# STM32U585 register map
File version: 1.4
CPU: CM33 r0p1, little endian, MPU, FPU, 4 interrupt priority bits
Registers are 32-bit, read-write, reset 0x0 unless marked. A register's access mark holds for its fields unless they carry their own. Offsets are from the block's base; [hi:lo] are bit positions; {n}, {i} and the like mark numbered series.

## ICACHE
Base 0x40030400
Same registers: SEC_ICache 0x50030400
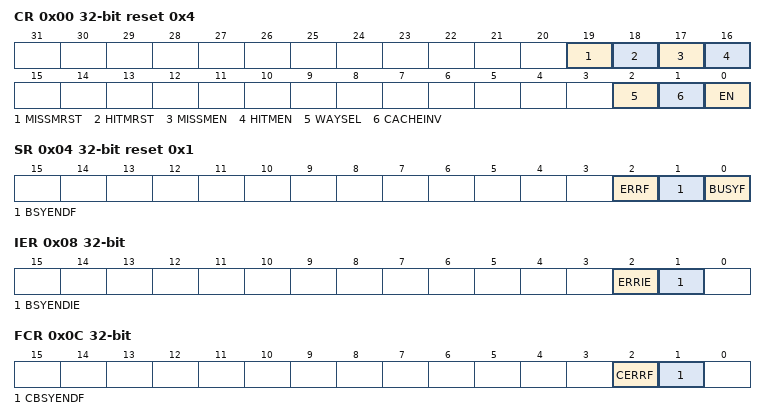
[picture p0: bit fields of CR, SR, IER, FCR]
0x00 CR access per field reset 0x4 — ICACHE control register
  [19] MISSMRST rw, [18] HITMRST rw, [17] MISSMEN rw, [16] HITMEN rw, [2] WAYSEL rw, [1] CACHEINV wo, [0] EN rw
0x04 SR ro reset 0x1 — ICACHE status register
  [2] ERRF, [1] BSYENDF, [0] BUSYF
0x08 IER — ICACHE interrupt enable register
  [2] ERRIE, [1] BSYENDIE
0x0C FCR wo — ICACHE flag clear register
  [2] CERRF, [1] CBSYENDF
0x10 HMONR ro — ICACHE hit monitor register
  [31:0] HITMON
0x14 MMONR ro — ICACHE miss monitor register
  [15:0] MISSMON
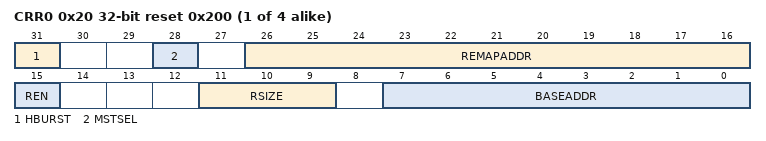
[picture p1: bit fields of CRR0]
{0x20+4i} CRR{i} reset 0x200 (i=0..3) — ICACHE region configuration register
  [31] HBURST, [28] MSTSEL, [26:16] REMAPADDR, [15] REN, [11:9] RSIZE, [7:0] BASEADDR

## DCACHE
Base 0x40031400
Same registers: SEC_DCACHE 0x50031400
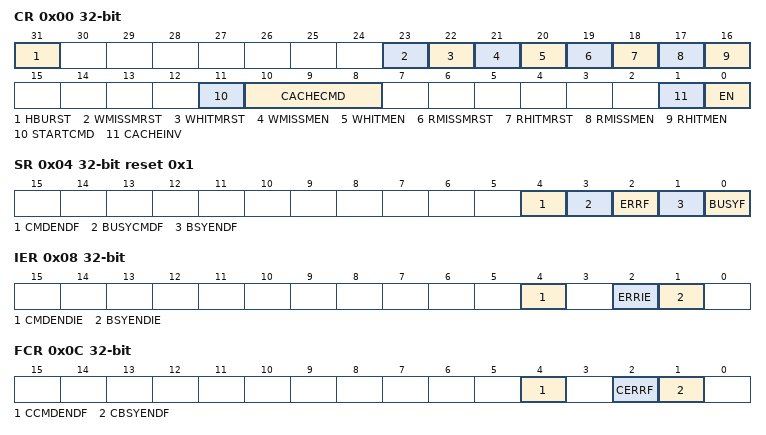
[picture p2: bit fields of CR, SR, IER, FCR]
0x00 CR access per field — DCACHE control register
  [31] HBURST rw, [23] WMISSMRST rw, [22] WHITMRST rw, [21] WMISSMEN rw, [20] WHITMEN rw, [19] RMISSMRST rw, [18] RHITMRST rw, [17] RMISSMEN rw, [16] RHITMEN rw, [11] STARTCMD wo, [10:8] CACHECMD rw, [1] CACHEINV wo, [0] EN rw
0x04 SR ro reset 0x1 — DCACHE status register
  [4] CMDENDF, [3] BUSYCMDF, [2] ERRF, [1] BSYENDF, [0] BUSYF
0x08 IER — DCACHE interrupt enable register
  [4] CMDENDIE, [2] ERRIE, [1] BSYENDIE
0x0C FCR wo — DCACHE flag clear register
  [4] CCMDENDF, [2] CERRF, [1] CBSYENDF
0x10 RHMONR ro — DCACHE read-hit monitor register
  [31:0] RHITMON
0x14 RMMONR ro — DCACHE read-miss monitor register
  [15:0] MRISSMON — RMISSMON
0x20 WHMONR ro — write-hit monitor register
  [31:0] WHITMON
0x24 WMMONR ro — write-miss monitor register
  [15:0] WMISSMON
0x28 CMDRSADDRR — command range start address register
  [31:0] CMDSTARTADDR
0x2C CMDREADDRR — command range start address register
  [31:0] CMDENDADDR

## IWDG — Independent watchdog
Base 0x40003000
Same registers: SEC_IWDG 0x50003000
0x00 KR 16-bit wo — Key register
  [15:0] KEY — Key value (write only, read 0x0000)
0x04 PR 16-bit — Prescaler register
  [3:0] PR — Prescaler divider
0x08 RLR 16-bit reset 0xFFF — Reload register
  [11:0] RL — Watchdog counter reload value
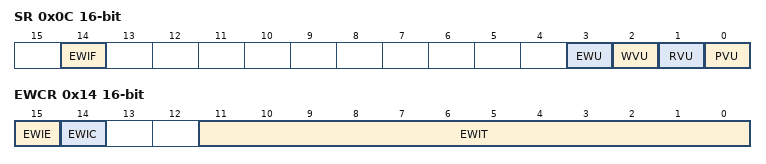
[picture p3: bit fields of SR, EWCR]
0x0C SR 16-bit ro — Status register
  [14] EWIF — Watchdog Early interrupt flag
  [3] EWU — Watchdog interrupt comparator value update
  [2] WVU — Watchdog counter window value update
  [1] RVU — Watchdog counter reload value update
  [0] PVU — Watchdog prescaler value update
0x10 WINR 16-bit reset 0xFFF — Window register
  [11:0] WIN — Watchdog counter window value
0x14 EWCR 16-bit — IWDG early wakeup interrupt register
  [15] EWIE — Watchdog early interrupt enable
  [14] EWIC — Watchdog early interrupt acknowledge
  [11:0] EWIT — Watchdog counter window value

## GTZC1_MPCBB1
Base 0x40032C00
Same registers: GTZC1_MPCBB2 0x40033000, GTZC1_MPCBB3 0x40033400, SEC_GTZC1_MPCBB1 0x50032C00, SEC_GTZC1_MPCBB2 0x50033000, SEC_GTZC1_MPCBB3 0x50033400
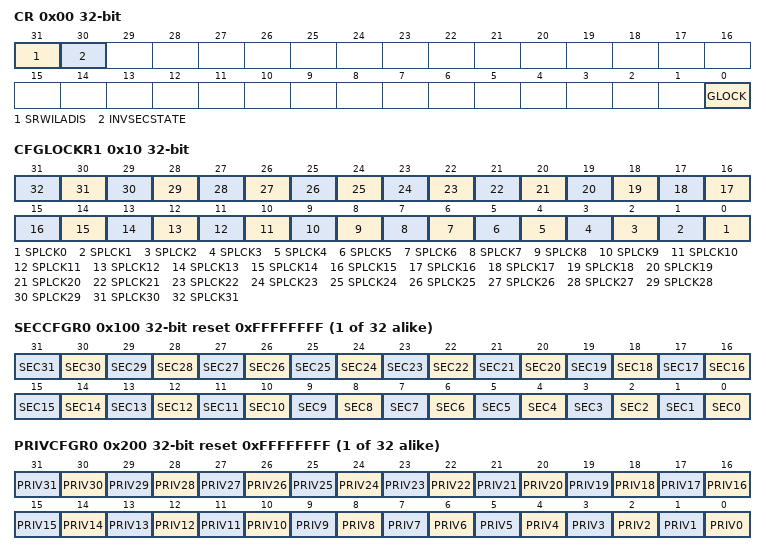
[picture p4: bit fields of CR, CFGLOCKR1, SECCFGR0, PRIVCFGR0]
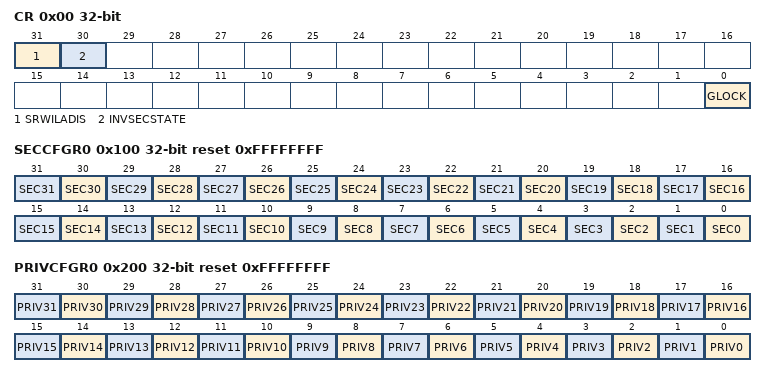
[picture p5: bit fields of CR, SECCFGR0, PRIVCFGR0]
0x00 CR — MPCBB control register
  [31] SRWILADIS — secure read/write illegal access disable
  [30] INVSECSTATE — SRAMx clocks security state
  [0] GLOCK — lock the control register of the MPCBB until next reset
0x10 CFGLOCKR1 — GTZC1 SRAMz MPCBB configuration lock register
  [n] SPLCK{n} (n=0..31) — SPLCK{n}
{0x100+4i} SECCFGR{i} (i=0..31) reset 0xFFFFFFFF — MPCBBz security configuration for super-block {i} register
  [n] SEC{n} (n=0..31) — SEC{n}
{0x200+4i} PRIVCFGR{i} (i=0..31) reset 0xFFFFFFFF — MPCBBz privileged configuration for super-block {i} register
  [n] PRIV{n} (n=0..31) — PRIV{n}

## GTZC2_MPCBB4
Base 0x46023800
Same registers: SEC_GTZC2_MPCBB4 0x56023800
0x00 CR — MPCBB control register
  [31] SRWILADIS — secure read/write illegal access disable
  [30] INVSECSTATE — SRAMx clocks security state
  [0] GLOCK — lock the control register of the MPCBB until next reset
0x10 CFGLOCK — GTZC2 SRAM4 MPCBB configuration lock register
  [n] SPLCK{n} (n=0..0) — Security/privilege configuration lock for super-block {n}
{0x100+4i} SECCFGR{i} (i=0..0) reset 0xFFFFFFFF — MPCBBz security configuration for super-block {i} register
  [n] SEC{n} (n=0..31) — SEC{n}
{0x200+4i} PRIVCFGR{i} (i=0..0) reset 0xFFFFFFFF — MPCBBz privileged configuration for super-block {i} register
  [n] PRIV{n} (n=0..31) — PRIV{n}
